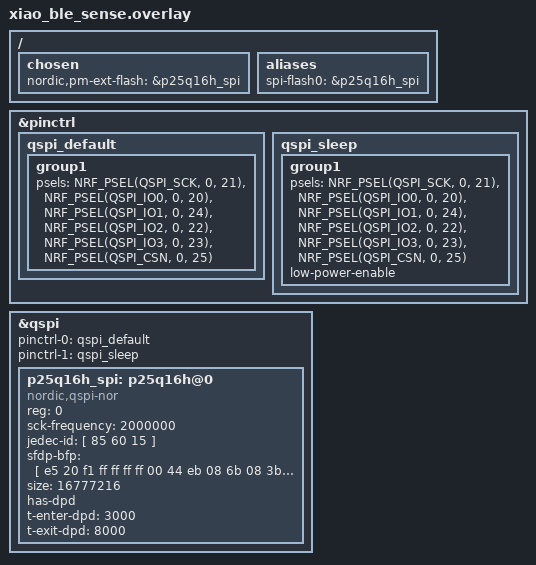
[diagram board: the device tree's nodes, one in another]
/delete-node/ &mx25r64;

/ {
    chosen {
        nordic,pm-ext-flash = &p25q16h_spi;
    };

    /* These aliases are provided for compatibility with samples */
    aliases {
        spi-flash0 = &p25q16h_spi;
    };
};

&pinctrl {
    qspi_default: qspi_default {
        group1 {
            psels = <NRF_PSEL(QSPI_SCK, 0, 21)>,
                    <NRF_PSEL(QSPI_IO0, 0, 20)>,
                    <NRF_PSEL(QSPI_IO1, 0, 24)>,
                    <NRF_PSEL(QSPI_IO2, 0, 22)>,
                    <NRF_PSEL(QSPI_IO3, 0, 23)>,
                    <NRF_PSEL(QSPI_CSN, 0, 25)>;
        };
    };

    qspi_sleep: qspi_sleep {
        group1 {
            psels = <NRF_PSEL(QSPI_SCK, 0, 21)>,
                    <NRF_PSEL(QSPI_IO0, 0, 20)>,
                    <NRF_PSEL(QSPI_IO1, 0, 24)>,
                    <NRF_PSEL(QSPI_IO2, 0, 22)>,
                    <NRF_PSEL(QSPI_IO3, 0, 23)>,
                    <NRF_PSEL(QSPI_CSN, 0, 25)>;
            low-power-enable;
        };
    };

};


&qspi {
    status = "okay";
    pinctrl-0 = <&qspi_default>;
    pinctrl-1 = <&qspi_sleep>;
    pinctrl-names = "default", "sleep";

    p25q16h_spi: p25q16h@0 {
        compatible = "nordic,qspi-nor";
        reg = <0>;
        sck-frequency = <2000000>;
        jedec-id = [ 85 60 15  ];
        sfdp-bfp = [ e5 20 f1 ff ff ff ff 00 44 eb 08 6b 08 3b 80 bb ee ff ff ff ff ff 00 ff ff ff 00 ff 0c 20 0f 52 10 d8 08 81  ];
        size = <16777216>;
        has-dpd;
        t-enter-dpd = <3000>;
        t-exit-dpd = <8000>;
    };
};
